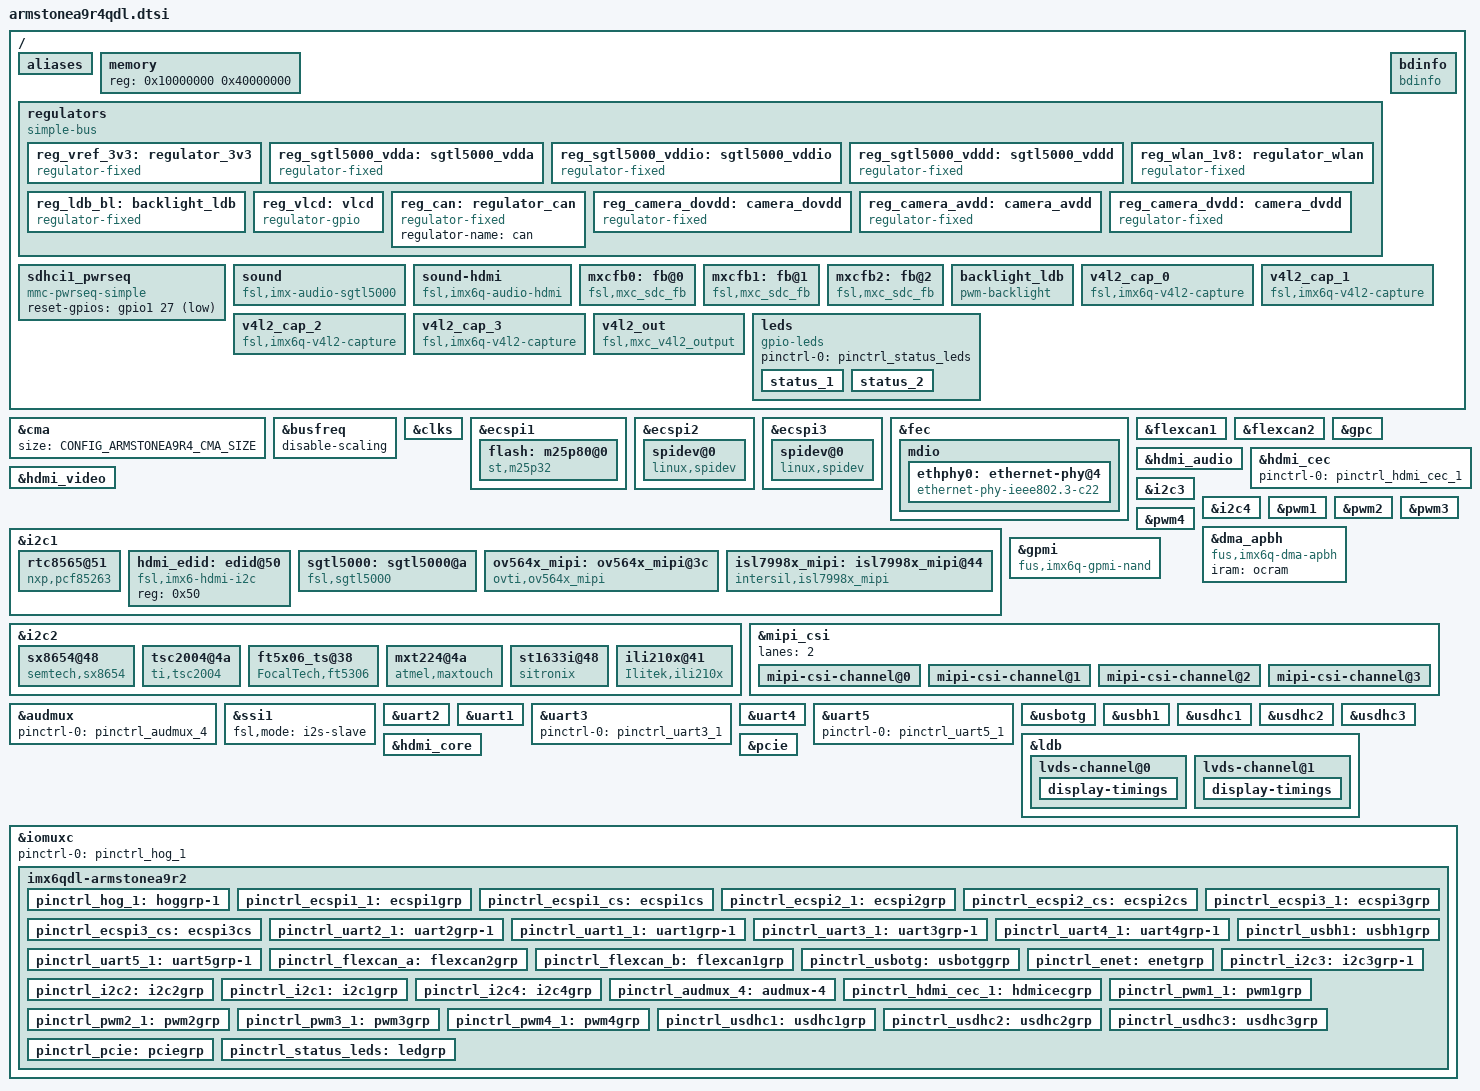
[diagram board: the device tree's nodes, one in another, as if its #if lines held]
/*
 * Copyright 2016-2017 F&S Elektronik Systeme GmbH
 *
 * This program is free software; you can redistribute it and/or modify
 * it under the terms of the GNU General Public License version 2 as
 * published by the Free Software Foundation.
 */

#include <dt-bindings/pwm/pwm.h>

/* Do we have HDMI? */
#if ((CONFIG_ARMSTONEA9R4_MXCFB0 == DISPLAY_HDMI) \
    || (CONFIG_ARMSTONEA9R4_MXCFB1 == DISPLAY_HDMI) \
    || (CONFIG_ARMSTONEA9R4_MXCFB2 == DISPLAY_HDMI))
#define CONFIG_ARMSTONEA9R4_HDMI
#define CONFIG_ARMSTONEA9R4_HDMI_AUDIO
#define CONFIG_ARMSTONEA9R4_HDMI_CEC
#if ((CONFIG_ARMSTONEA9R4_MXCFB0 == DISPLAY_HDMI) \
    || (CONFIG_ARMSTONEA9R4_MXCFB1 == DISPLAY_HDMI))
#define __HDMI_ON_0_OR_1__	1
#else
#define __HDMI_ON_0_OR_1__	0
#endif
#endif

/* Do we have LVDS0? */
#if ((CONFIG_ARMSTONEA9R4_MXCFB0 == DISPLAY_LVDS0) \
    || (CONFIG_ARMSTONEA9R4_MXCFB1 == DISPLAY_LVDS0) \
    || (CONFIG_ARMSTONEA9R4_MXCFB2 == DISPLAY_LVDS0))
#define CONFIG_ARMSTONEA9R4_LVDS0
#if ((CONFIG_ARMSTONEA9R4_MXCFB0 == DISPLAY_LVDS0) \
    || (CONFIG_ARMSTONEA9R4_MXCFB1 == DISPLAY_LVDS0))
#define __LVDS0_ON_0_OR_1__	1
#else
#define __LVDS0_ON_0_OR_1__	0
#endif
#endif

/* Do we have LVDS1? */
#if ((CONFIG_ARMSTONEA9R4_MXCFB0 == DISPLAY_LVDS1) \
    || (CONFIG_ARMSTONEA9R4_MXCFB1 == DISPLAY_LVDS1) \
    || (CONFIG_ARMSTONEA9R4_MXCFB2 == DISPLAY_LVDS1))
#define CONFIG_ARMSTONEA9R4_LVDS1
#if ((CONFIG_ARMSTONEA9R4_MXCFB0 == DISPLAY_LVDS1) \
    || (CONFIG_ARMSTONEA9R4_MXCFB1 == DISPLAY_LVDS1))
#define __LVDS1_ON_0_OR_1__	1
#else
#define __LVDS1_ON_0_OR_1__	0
#endif
#endif

/* Check which LVDS will be the primary display */
#if (CONFIG_ARMSTONEA9R4_MXCFB0 == DISPLAY_LVDS0)
#define __LVDS0_PRIMARY__
#elif (CONFIG_ARMSTONEA9R4_MXCFB0 == DISPLAY_LVDS1)
#define __LVDS1_PRIMARY__
#elif (CONFIG_ARMSTONEA9R4_MXCFB1 == DISPLAY_LVDS0)
#define __LVDS0_PRIMARY__
#elif (CONFIG_ARMSTONEA9R4_MXCFB1 == DISPLAY_LVDS1)
#define __LVDS1_PRIMARY__
#elif (CONFIG_ARMSTONEA9R4_MXCFB2 == DISPLAY_LVDS0)
#define __LVDS0_PRIMARY__
#elif (CONFIG_ARMSTONEA9R4_MXCFB2 == DISPLAY_LVDS1)
#define __LVDS1_PRIMARY__
#endif

/ {
	aliases {
		mxcfb0 = &mxcfb0;
		mxcfb1 = &mxcfb1;
		mxcfb2 = &mxcfb2;
		nand = &gpmi;
	};

	memory {
		reg = <0x10000000 0x40000000>;
	};

	regulators {
		compatible = "simple-bus";

		reg_vref_3v3: regulator_3v3 {
			compatible = "regulator-fixed";
			regulator-name = "vref-3V3";
			regulator-min-microvolt = <3300000>;
			regulator-max-microvolt = <3300000>;
			regulator-always-on;
		};

		/* USB_OTG_PWR handled by USB controller, no regulator needed */
#if 0 //###
		reg_usb_otg_vbus: usb_otg_vbus {
			compatible = "regulator-fixed";
			regulator-name = "usb_otg_vbus";
			regulator-min-microvolt = <5000000>;
			regulator-max-microvolt = <5000000>;
			gpio = <&gpio3 22 GPIO_ACTIVE_LOW>;
		};
#endif //###

		/* USB_H1_PWR is always on, no regulator needed */
#if 0 //###
		reg_usb_h1_vbus: usb_h1_vbus {
			compatible = "regulator-fixed";
			regulator-name = "usb_h1_vbus";
			regulator-min-microvolt = <5000000>;
			regulator-max-microvolt = <5000000>;
			/* No way to switch USB1_H1_VBUS power */
			regulator-always-on;
		};
#endif //###

#ifdef CONFIG_ARMSTONEA9R4_SGTL5000_AUDIO
		/* SGTL5000 analog voltage */
		reg_sgtl5000_vdda: sgtl5000_vdda {
			compatible = "regulator-fixed";
			regulator-name = "VDDA-supply";
			regulator-min-microvolt = <3000000>;
			regulator-max-microvolt = <3000000>;
			regulator-always-on;
		};

		/* SGTL5000 I/O voltage */
		reg_sgtl5000_vddio: sgtl5000_vddio {
			compatible = "regulator-fixed";
			regulator-name = "VDDIO-supply";
			regulator-min-microvolt = <3300000>;
			regulator-max-microvolt = <3300000>;
			regulator-always-on;
		};

		/* SGTL5000 internal digital voltage */
		reg_sgtl5000_vddd: sgtl5000_vddd {
			compatible = "regulator-fixed";
			regulator-name = "VDDD-supply";
			regulator-min-microvolt = <1500000>;
			regulator-max-microvolt = <1500000>;
			regulator-always-on;
		};
#endif /* CONFIG_ARMSTONEA9R4_SGTL5000_AUDIO */

#ifdef CONFIG_ARMSTONEA9R4_WLAN
		reg_wlan_1v8: regulator_wlan {
			compatible = "regulator-fixed";
			regulator-name = "vqmmc-wlan-1v8";
			regulator-min-microvolt = <1800000>;
			regulator-max-microvolt = <1800000>;
			regulator-always-on;
		};
#endif

		/* backlight ldb */
		reg_ldb_bl: backlight_ldb {
			compatible = "regulator-fixed";
			regulator-name = "ldb-bl";
			gpio = <&gpio2 8 GPIO_ACTIVE_HIGH>;
			regulator-min-microvolt = <3300000>;
			regulator-max-microvolt = <3300000>;
			enable-active-high;
		};

		/* LCD power on voltage */
		reg_vlcd: vlcd {
			compatible = "regulator-gpio";
			regulator-name = "VLCD";
			regulator-min-microvolt = <3300000>;
			regulator-max-microvolt = <5000000>;

			enable-gpio = <&gpio2 11 GPIO_ACTIVE_HIGH>;
			gpios = <&gpio3 30 GPIO_ACTIVE_HIGH>;
#ifdef CONFIG_ARMSTONEA9R4_LVDS_3_3_V
			gpios-states = <0>;
#elif defined(CONFIG_ARMSTONEA9R4_LVDS_5_0_V)
			gpios-states = <1>;
#endif
			states = <5000000 0x1
				3300000 0x0>;
			enable-active-high;
		};

		/* CAN */
		reg_can: regulator_can {
			compatible = "regulator-fixed";
			regulator-name = "can";
		};

#ifdef CONFIG_ARMSTONEA9R4_SERIAL_CAMERA
		reg_camera_dovdd: camera_dovdd {
			compatible = "regulator-fixed";
			regulator-name = "DOVDD-supply";
			regulator-min-microvolt = <1800000>;
			regulator-max-microvolt = <1800000>;
		};

		reg_camera_avdd: camera_avdd {
			compatible = "regulator-fixed";
			regulator-name = "VAVDD-supply";
			regulator-min-microvolt = <2800000>;
			regulator-max-microvolt = <2800000>;
		};

		reg_camera_dvdd: camera_dvdd {
			compatible = "regulator-fixed";
			regulator-name = "DVDD-supply";
			regulator-min-microvolt = <1500000>;
			regulator-max-microvolt = <1500000>;
		};
#endif /* CONFIG_ARMSTONEA9R4_SERIAL_CAMERA */
	};

	/* F&S board information */
	bdinfo: bdinfo {
		compatible = "bdinfo";
		board_name = "armstonea9r2";
		ecc_strength = "8";
	};

	sdhci1_pwrseq: sdhci1_pwrseq {
		compatible = "mmc-pwrseq-simple";
		reset-gpios = <&gpio1 27 GPIO_ACTIVE_LOW>;
	};

#ifdef CONFIG_ARMSTONEA9R4_SGTL5000_AUDIO
	sound {
		compatible = "fsl,imx-audio-sgtl5000";
		cpu-dai = <&ssi1>;
		audio-codec = <&sgtl5000>;
		model = "imx-sgtl5000";
		mux-int-port = <1>;  /* SSI1=1, SSI2=2, SSI3=7 */
		mux-ext-port = <4>;
		audio-routing =
//			"MIC_IN", "Mic Jack",
			"Mic Jack", "Mic Bias",
			"LINE_IN", "Line In Jack";
//			"Line Out Jack", "LINE_OUT";
	};
#endif

#ifdef CONFIG_ARMSTONEA9R4_HDMI_AUDIO
	sound-hdmi {
		compatible = "fsl,imx6q-audio-hdmi", "fsl,imx-audio-hdmi";
		model = "imx-audio-hdmi";
		hdmi-controller = <&hdmi_audio>;
	};
#endif

	mxcfb0: fb@0 {
		compatible = "fsl,mxc_sdc_fb";
		late_init = <0>;
#if (CONFIG_ARMSTONEA9R4_MXCFB0 == DISPLAY_HDMI)
		disp_dev = "hdmi";
		default_bpp = <CONFIG_ARMSTONEA9R4_HDMI_BPP>;
		interface_pix_fmt = CONFIG_ARMSTONEA9R4_HDMI_PIX_FMT;
		int_clk = <0>;
		mode_str = CONFIG_ARMSTONEA9R4_HDMI_MODE_STR;
#elif (CONFIG_ARMSTONEA9R4_MXCFB0 == DISPLAY_LVDS0)
		disp_dev = "ldb";
		default_bpp = <CONFIG_ARMSTONEA9R4_LVDS0_BPP>;
		interface_pix_fmt = CONFIG_ARMSTONEA9R4_LVDS0_PIX_FMT;
		int_clk = <1>;
#elif (CONFIG_ARMSTONEA9R4_MXCFB0 == DISPLAY_LVDS1)
		disp_dev = "ldb";
		default_bpp = <CONFIG_ARMSTONEA9R4_LVDS1_BPP>;
		interface_pix_fmt = CONFIG_ARMSTONEA9R4_LVDS1_PIX_FMT;
		int_clk = <1>;
#else
		status = "disabled";
#endif
	};

	mxcfb1: fb@1 {
		compatible = "fsl,mxc_sdc_fb";
		late_init = <0>;
#if (CONFIG_ARMSTONEA9R4_MXCFB1 == DISPLAY_HDMI)
		disp_dev = "hdmi";
		default_bpp = <CONFIG_ARMSTONEA9R4_HDMI_BPP>;
		interface_pix_fmt = CONFIG_ARMSTONEA9R4_HDMI_PIX_FMT;
		int_clk = <0>;
		mode_str = CONFIG_ARMSTONEA9R4_HDMI_MODE_STR;
#elif (CONFIG_ARMSTONEA9R4_MXCFB1 == DISPLAY_LVDS0)
		disp_dev = "ldb";
		default_bpp = <CONFIG_ARMSTONEA9R4_LVDS0_BPP>;
		interface_pix_fmt = CONFIG_ARMSTONEA9R4_LVDS0_PIX_FMT;
		int_clk = <1>;
#elif (CONFIG_ARMSTONEA9R4_MXCFB1 == DISPLAY_LVDS1)
		disp_dev = "ldb";
		default_bpp = <CONFIG_ARMSTONEA9R4_LVDS1_BPP>;
		interface_pix_fmt = CONFIG_ARMSTONEA9R4_LVDS1_PIX_FMT;
		int_clk = <1>;
#else
		status = "disabled";
#endif
	};

	mxcfb2: fb@2 {
		compatible = "fsl,mxc_sdc_fb";
		late_init = <0>;
#if (CONFIG_ARMSTONEA9R4_MXCFB2 == DISPLAY_HDMI)
		disp_dev = "hdmi";
		default_bpp = <CONFIG_ARMSTONEA9R4_HDMI_BPP>;
		interface_pix_fmt = CONFIG_ARMSTONEA9R4_HDMI_PIX_FMT;
		int_clk = <0>;
		mode_str = CONFIG_ARMSTONEA9R4_HDMI_MODE_STR;
#elif (CONFIG_ARMSTONEA9R4_MXCFB2 == DISPLAY_LVDS0)
		disp_dev = "ldb";
		default_bpp = <CONFIG_ARMSTONEA9R4_LVDS0_BPP>;
		interface_pix_fmt = CONFIG_ARMSTONEA9R4_LVDS0_PIX_FMT;
		int_clk = <1>;
#elif (CONFIG_ARMSTONEA9R4_MXCFB2 == DISPLAY_LVDS1)
		disp_dev = "ldb";
		default_bpp = <CONFIG_ARMSTONEA9R4_LVDS1_BPP>;
		interface_pix_fmt = CONFIG_ARMSTONEA9R4_LVDS1_PIX_FMT;
		int_clk = <1>;
#else
		status = "disabled";
#endif
	};

	/* LVDS backlight PWM (PWM3) */
	backlight_ldb {
		compatible = "pwm-backlight";
		power-supply = <&reg_ldb_bl>;
#ifndef DISPLAY_LVDS_CHIMEI
		pwms = <&pwm3 0 250000 PWM_POLARITY_INVERTED>;
		brightness-levels = <135 143 151 159 167 175 183 191
				     199 207 215 223 231 239 247 255>;
#else
		pwms = <&pwm3 0 5000000 0>;
		brightness-levels = <0 1 5 10 18 28 41 56
				     73 92 113 137 163 192 222 255>;
#endif
		default-brightness-level = <14>;
		fb-names = "ldb0", "ldb1";
	};

/* mipi camera interface */
#ifdef CONFIG_ARMSTONEA9R4_SERIAL_CAMERA
	v4l2_cap_0 {
		compatible = "fsl,imx6q-v4l2-capture";
		ipu_id = <0>;
		csi_id = <0>;
		mclk_source = <0>;
		status = "okay";
	};

	/* Second capture device, for second MIPI channel */
	v4l2_cap_1 {
		compatible = "fsl,imx6q-v4l2-capture";
		ipu_id = <0>;
		csi_id = <1>;
		mclk_source = <0>;
		status = "okay";
	};

#ifndef CONFIG_ARMSTONEA9R4_USE_ONE_IPU
	/* Third capture device, for third MIPI channel */
	v4l2_cap_2 {
		compatible = "fsl,imx6q-v4l2-capture";
		ipu_id = <1>;
		csi_id = <0>;
		mclk_source = <0>;
		status = "okay";
	};

	/* Fourth capture device, for fourth MIPI channel */
	v4l2_cap_3 {
		compatible = "fsl,imx6q-v4l2-capture";
		ipu_id = <1>;
		csi_id = <1>;
		mclk_source = <0>;
		status = "okay";
	};
#endif
#endif

	v4l2_out {
		compatible = "fsl,mxc_v4l2_output";
		status = "okay";
	};

	leds {
		compatible = "gpio-leds";
		pinctrl-names = "default";
		pinctrl-0 = <&pinctrl_status_leds>;

		status_1 {
			label = "Status1";
			gpios = <&gpio7 13 GPIO_ACTIVE_HIGH>;
			default-state = "keep";
		};

		status_2 {
			label = "Status2";
			gpios = <&gpio7 12 GPIO_ACTIVE_HIGH>;
			default-state = "keep";
		};
	};

/* Matrix Keypad not configurated yet, some pins can be multiple declared*/
#if 0
		matrix-keypad {
		compatible = "gpio-matrix-keypad";
		pinctrl-names = "default";
		pinctrl-0 = <&pinctrl_gpio_matrix_keypad>;
		debounce-delay-ms = <10>;
		col-scan-delay-us = <2>;
		linux,no-autorepeat;

		row-gpios = <&gpio5 28 0
			     &gpio3 28 0
			     &gpio5 29 0
			     &gpio3 29 0
			     &gpio3 19 0
			     &gpio3 24 0
			     &gpio3 20 0
			     &gpio3 25 0
			     >;

		col-gpios = <&gpio4 21 0
			     &gpio3 0 0
			     &gpio4 24 0
			     &gpio3 1 0
			     &gpio4 22 0
			     &gpio3 2 0
			     &gpio4 23 0
			     &gpio3 3 0>;
		/* needs to be configurated, Vybrid Kernel has so config file
		 * "fs-matrix-keypad.h" */
		linux,keymap = <>;
	};
#endif

};

/* RAM size for Continuous Memory Allocator; if not defined, use 320 MB */
#ifndef CONFIG_ARMSTONEA9R4_CMA_SIZE
#define CONFIG_ARMSTONEA9R4_CMA_SIZE 0x14000000
#endif
&cma {
	size = <CONFIG_ARMSTONEA9R4_CMA_SIZE>;
};

&busfreq {
	/* Disable bus frequency scaling, because reducing bus frequency to
	   24 MHz does not work with all types of DDR3 RAM */
	disable-scaling;
};

/* CKO (via CKO1): 24.576 MHz for Audio Codec, CKO2: 24 MHz for Camera. */
&clks {
	assigned-clocks =
#ifdef CONFIG_ARMSTONEA9R4_LVDS0_CLK
			  <&clks IMX6QDL_CLK_LDB_DI0_SEL>,
#endif
#ifdef CONFIG_ARMSTONEA9R4_LVDS1_CLK
			  <&clks IMX6QDL_CLK_LDB_DI1_SEL>,
#endif
			  <&clks IMX6QDL_CLK_PLL4_AUDIO_DIV>,
			  <&clks IMX6QDL_CLK_CKO1_SEL>,
			  <&clks IMX6QDL_CLK_CKO1_PODF>,
			  <&clks IMX6QDL_CLK_CKO>,
			  <&clks IMX6QDL_CLK_CKO2_SEL>;

	assigned-clock-parents =
#ifdef CONFIG_ARMSTONEA9R4_LVDS0_CLK
				 <&clks CONFIG_ARMSTONEA9R4_LVDS0_CLK>,
#endif
#ifdef CONFIG_ARMSTONEA9R4_LVDS1_CLK
				 <&clks CONFIG_ARMSTONEA9R4_LVDS1_CLK>,
#endif
				 <0>,
				 <&clks IMX6QDL_CLK_PLL4_AUDIO_DIV>,
				 <0>,
				 <&clks IMX6QDL_CLK_CKO1>,
 				 <&clks IMX6QDL_CLK_OSC>;

	/*
	 * The Audio-PLL (PLL4) must have at least 650MHz. The PLL post divider
	 * can divide by 1, 2 and 4, which means the lowest possible frequency
	 * is 162.5 MHz. The largest PODF divider for CKO1 is 8, so we do not
	 * get below 20 MHz. Use 24.576 MHz as this is a multiple of the most
	 * commonly used bit rates.
	 *
	 * Remark: Solo and DualLite have an additional divider that also can
	 * divide by 1, 2 and 4. So here we can go down to 12.288 MHz.
	 */
	assigned-clock-rates =
#ifdef CONFIG_ARMSTONEA9R4_LVDS0_CLK
			      <0>,
#endif
#ifdef CONFIG_ARMSTONEA9R4_LVDS1_CLK
			      <0>,
#endif
#ifdef CONFIG_ARMSTONEA9R4_AUDIO_12M288
			      <98304000>,	/* Audio with 12.288 MHz */
			      <98304000>,
			      <12288000>,
#else
			      <196608000>,	/* Audio with 24.576 MHz */
			      <196608000>,
			      <24576000>,
#endif
			      <24000000>;
};

#ifdef CONFIG_ARMSTONEA9R4_SPI_FLASH
/* Optional on-board SPI flash (1x CS) */
&ecspi1 {
	fsl,spi-num-chipselects = <2>;
	cs-gpios = <&gpio2 30 GPIO_ACTIVE_HIGH>;
	pinctrl-names = "default";
	pinctrl-0 = <&pinctrl_ecspi1_1 &pinctrl_ecspi1_cs>;
	status = "okay";

	flash: m25p80@0 {
		#address-cells = <1>;
		#size-cells = <1>;
		compatible = "st,m25p32";
		spi-max-frequency = <20000000>;
		reg = <0>;
	};
};
#endif /* CONFIG_ARMSTONEA9R4_SPI_FLASH */

#ifdef CONFIG_ARMSTONEA9R4_SPI_A
/* SPI_A (1x CS) */
&ecspi2 {
	fsl,spi-num-chipselects = <2>;
	cs-gpios = <&gpio2 26 GPIO_ACTIVE_HIGH>;
	pinctrl-names = "default";
	pinctrl-0 = <&pinctrl_ecspi2_1 &pinctrl_ecspi2_cs>;
	status = "okay";

	spidev@0 {
		#address-cells = <1>;
		#size-cells = <1>;
		compatible = "linux,spidev";
		spi-max-frequency = <20000000>;
		reg = <0>;
	};
};
#endif /* CONFIG_ARMSTONEA9R4_SPI_A */

#ifdef CONFIG_ARMSTONEA9R4_SPI_B
/* SPI_B (1x CS) */
&ecspi3 {
	fsl,spi-num-chipselects = <2>;
	cs-gpios = <&gpio4 24 GPIO_ACTIVE_HIGH>;
	pinctrl-names = "default";
	pinctrl-0 = <&pinctrl_ecspi3_1 &pinctrl_ecspi3_cs>;
	status = "okay";

	spidev@0 {
		#address-cells = <1>;
		#size-cells = <1>;
		compatible = "linux,spidev";
		spi-max-frequency = <20000000>;
		reg = <0>;
	};
};
#endif /* CONFIG_ARMSTONEA9R4_SPI_B */

&fec {
	pinctrl-names = "default";
	pinctrl-0 = <&pinctrl_enet>;
	phy-mode = "rgmii-id";
	phy-handle = <&ethphy0>;
	phy-supply = <&reg_vref_3v3>;
	status = "okay";

	mdio {
		#address-cells = <1>;
		#size-cells = <0>;

		ethphy0: ethernet-phy@4 {
			compatible = "ethernet-phy-ieee802.3-c22";
			reg = <4>;
			/* Set the maximum link speed if required */
			//max-speed = <100>;
			rtl821x,aldps-enable;
			rtl821x,ssc-rxc-enable;
			rtl821x,ssc-sysclk-enable;
			rtl821x,ssc-clkout-enable;
			rtl821x,led-link = <2>;
			rtl821x,led-act = <1>;
		};
	};
};

/* CANRX2 J13 Pin 3 & CANTX2 Pin 4 */
&flexcan1 {
	pinctrl-names = "default";
	pinctrl-0 = <&pinctrl_flexcan_b>;
	xceiver-supply = <&reg_can>;
	status = "okay";
};

/* CANRX1 Pin 63 & CANTX1 Pin 64 */
&flexcan2 {
	pinctrl-names = "default";
	pinctrl-0 = <&pinctrl_flexcan_a>;
	xceiver-supply = <&reg_can>;
	status = "okay";
};

&gpc {
	fsl,cpu_pupscr_sw2iso = <0xf>;
	fsl,cpu_pupscr_sw = <0xf>;
	fsl,cpu_pdnscr_iso2sw = <0x1>;
	fsl,cpu_pdnscr_iso = <0x1>;
	fsl,ldo-bypass = <1>; /* use ldo-bypass, u-boot will check it and configure */
	fsl,wdog-reset = <1>; /* watchdog select of reset source */
};

#ifdef CONFIG_ARMSTONEA9R4_HDMI_AUDIO
&hdmi_audio {
	status = "okay";
};
#endif

#ifdef CONFIG_ARMSTONEA9R4_HDMI_CEC
&hdmi_cec {
	pinctrl-names = "default";
	pinctrl-0 = <&pinctrl_hdmi_cec_1>;
	status = "okay";
};
#endif

#ifdef CONFIG_ARMSTONEA9R4_HDMI
&hdmi_video {
	fsl,phy_reg_vlev = <0x0294>;
	fsl,phy_reg_cksymtx = <0x800d>;
	force-dvi-mode;
	status = "okay";
};
#endif

#ifdef CONFIG_ARMSTONEA9R4_I2C_C
/* additional bus on pins 18, 26 */
&i2c1 {
	clock-frequency = <100000>;
	pinctrl-names = "default";
	pinctrl-0 = <&pinctrl_i2c1>;
	status = "okay";

	rtc8565@51 {
		compatible = "nxp,pcf85263";
		reg = <0x51>;
		interrupt-parent = <&gpio1>;
		interrupts = <28 IRQ_TYPE_EDGE_FALLING>;
	};

#ifdef CONFIG_ARMSTONEA9R4_HDMI
	hdmi_edid: edid@50 {
		compatible = "fsl,imx6-hdmi-i2c";
		reg = <0x50>;
	};
#endif

#ifdef CONFIG_ARMSTONEA9R4_SGTL5000_AUDIO
	sgtl5000: sgtl5000@a {
		compatible = "fsl,sgtl5000";
		reg = <0x0a>;
		mono2both;
		lrclk-strength = <3>;
		clocks = <&clks IMX6QDL_CLK_CKO>;
		VDDA-supply = <&reg_sgtl5000_vdda>;
		VDDIO-supply = <&reg_sgtl5000_vddio>;
		VDDD-supply = <&reg_sgtl5000_vddd>;
	};
#endif


/* If you want to use mipi camera you have to check the clock because cko2
 * is used by sgtl5000 audio driver so you have to change the &clk node to
 * ck01. Therefore you have to set PLL_AUDIO, CCM_ANALOG_MISC2n[MSB:LSB] */
#ifdef CONFIG_ARMSTONEA9R4_SERIAL_CAMERA
	ov564x_mipi: ov564x_mipi@3c {
		compatible = "ovti,ov564x_mipi";
		reg = <0x3c>;
		/* derived from IMX6QDL_CLK_CKO2 */
		clocks = <&clks IMX6QDL_CLK_CKO2>;
		clock-names = "csi_mclk";
		DOVDD-supply = <&reg_camera_dovdd>; /* 1.8v */
		AVDD-supply = <&reg_camera_avdd>;  /* 2.8v, rev C board is VGEN3
						rev B board is VGEN5 */
		DVDD-supply = <&reg_camera_dvdd>;  /* 1.5v*/
		pwn-gpios = <&gpio5 24 GPIO_ACTIVE_HIGH>;
		/* With our camera adapter we dont need a reset pin because the
		 * reset will be automatically generated on our adapter. Other
		 * cameras maybe need a gpio to perform a reset. */
		/* rst-gpios = <dummy>; */
		csi_id = <0>;
		v_channel_id = <0>;
		mclk = <24000000>;		/* OSC out */
		mclk_source = <0>;
	};
#ifdef CONFIG_ARMSTONEA9R4_MIPI_CAMERA_ISL7998X
	isl7998x_mipi: isl7998x_mipi@44 {
		compatible = "intersil,isl7998x_mipi";
		reg = <0x44>;
		clocks = <&clks IMX6QDL_CLK_CKO2>;	/* Dummy */
		clock-names = "csi_mclk";
		mclk = <27000000>;		/* Has own oscillator */
	};
#endif
#endif /* CONFIG_ARMSTONEA9R4_SERIAL_CAMERA */
};
#endif /* CONFIG_ARMSTONEA9R4_I2C_C */

#ifdef CONFIG_ARMSTONEA9R4_I2C_B
&i2c2 {
	clock-frequency = <100000>;
	pinctrl-names = "default";
	pinctrl-0 = <&pinctrl_i2c2>;
	status = "okay";

#ifdef CONFIG_ARMSTONEA9R4_4WTOUCH_SX8655
	/* 4/5 wire analog resistive touch on Touch Connector (I2C) */
	sx8654@48 {
		compatible = "semtech,sx8654";
		reg = <0x48>;
		touchrate = <0x30>;
		powdly = <0x06>;
		filt = <0x02>;
		setdly = <0x08>;
		pinctrl-names = "default";
		/* There are 2 irq pins for I2C2. You can either chose the irq from the
		 * lvds connector or from the hirose connector. below is the
		 * interrupt from lvds connector defined. Only one interrupt can
		 * be used for one touch. It is only possible if revision >= 1.20 and
		 * R223 is not mounted. If R223 is mounted we have the VLCD signal
		 * on the IRQ pin on LVDS connector (J11/26).
		 */
//#if (CONFIG_ARMSTONEA9R4_BOARD_REVISION >= 120)
		//interrupt-parent = <&gpio2>;
		//interrupts = <13 IRQ_TYPE_EDGE_FALLING>;
//#else
		interrupt-parent = <&gpio1>;
		interrupts = <30 IRQ_TYPE_EDGE_FALLING>;
		reset-gpio = <&gpio1 29 GPIO_ACTIVE_LOW>;
//#endif
	};
#endif

#ifdef CONFIG_ARMSTONEA9R4_4WTOUCH_TSC2004
	/* 4/5 wire analog resistive touch on Touch Connector (I2C) */
	tsc2004@4a {
		compatible = "ti,tsc2004";
		reg = <0x4a>;
		vio-supply = <&reg_vref_3v3>;
		interrupts-extended = <&gpio1 30 IRQ_TYPE_EDGE_FALLING>;
		reset-gpio = <&gpio1 29 GPIO_ACTIVE_LOW>;
		touchscreen-fuzz-x = <4>;
		touchscreen-fuzz-y = <7>;
		touchscreen-fuzz-pressure = <20>;
		touchscreen-size-x = <4096>;
		touchscreen-size-y = <4096>;
		touchscreen-max-pressure = <2048>;
		touchscreen-inverted-y;
		ti,x-plate-ohms = <280>;
		ti,pre-charge-time = <4>;
		ti,sense-time-sel = <3>;
	};
#endif

#ifdef CONFIG_ARMSTONEA9R4_CAPTOUCH_FT5x06
	/* F&S driver V3.0 on Touch Connector (I2C) */
	ft5x06_ts@38 {
		compatible = "FocalTech,ft5306";
		reg = <0x38>;
		fingers = <2>;
		touchscreen-size-x = <800>;
		touchscreen-size-y = <480>;
		threshold = <25>;
		/* There are 2 irq pins for I2C2. You can either chose the irq from the
		 * lvds connector or from the hirose connector. below is the
		 * interrupt from lvds connector defined. Only one interrupt can
		 * be used for one touch. It is only possible if revision >= 1.20 and
		 * R223 is not mounted. If R223 is mounted we have the VLCD signal
		 * on the IRQ pin on LVDS connector (J11/26).
		 */
//#if (CONFIG_ARMSTONEA9R4_BOARD_REVISION >= 120)
		//interrupt-parent = <&gpio2>;
		//interrupts = <13 IRQ_TYPE_EDGE_FALLING>;
//#else
		interrupt-parent = <&gpio1>;
		interrupts = <30 IRQ_TYPE_EDGE_FALLING>;
//#endif
		reset-gpios = <&gpio1 29 GPIO_ACTIVE_LOW>;
		x-rev;
		y-rev;
		linux,wakeup;
	};
#endif

#ifdef CONFIG_ARMSTONEA9R4_CAPTOUCH_MXT224
	/* Atmel PCAP touch on Touch Connector (I2C) */
	mxt224@4a {
		compatible = "atmel,maxtouch";
		reg = <0x4a>;
		/* There are 2 irq pins for I2C2. You can either chose the irq from the
		 * lvds connector or from the hirose connector. below is the
		 * interrupt from lvds connector defined. Only one interrupt can
		 * be used for one touch. It is only possible if revision >= 1.20 and
		 * R223 is not mounted. If R223 is mounted we have the VLCD signal
		 * on the IRQ pin on LVDS connector (J11/26).
		 */
//#if (CONFIG_ARMSTONEA9R4_BOARD_REVISION >= 120)
		//interrupt-parent = <&gpio2>;
		//interrupts = <13 IRQ_TYPE_EDGE_FALLING>;
//#else
		interrupt-parent = <&gpio1>;
		interrupts = <30 IRQ_TYPE_EDGE_FALLING>;
//#endif
		atmel,cfg_name = "atmel/mxt224.cfg";
		atmel,reset-gpio = <&gpio1 29 GPIO_ACTIVE_LOW>;
	};
#endif

#ifdef CONFIG_ARMSTONEA9_CAPTOUCH_SITRONIX
	/* Sitronix PCAP touch on Touch-Connector (I2C) */
	st1633i@48 {
		compatible = "sitronix";
		reg = <0x48>;
		swap-xy;
		/* There are 2 irq pins for I2C2. You can either chose the irq from the
		 * lvds connector or from the hirose connector. below is the
		 * interrupt from lvds connector defined. Only one interrupt can
		 * be used for one touch. It is only possible if revision >= 1.20 and
		 * R223 is not mounted. If R223 is mounted we have the VLCD signal
		 * on the IRQ pin on LVDS connector (J11/26).
		 */
//#if (CONFIG_ARMSTONEA9R4_BOARD_REVISION >= 120)
		//interrupt-parent = <&gpio2>;
		//interrupts = <13 IRQ_TYPE_EDGE_FALLING>;
//#else
		interrupt-parent = <&gpio1>;
		interrupts = <30 IRQ_TYPE_EDGE_FALLING>;
//#endif
		reset-gpio = <&gpio1 29 GPIO_ACTIVE_LOW>;
	};
#endif

#ifdef CONFIG_ARMSTONEA9_CAPTOUCH_ILITEK
	/* Ilitek PCAP touch on Touch-Connector (I2C) */
	ili210x@41 {
		compatible = "Ilitek,ili210x";
		reg = <0x41>;
		/* There are 2 irq pins for I2C2. You can either chose the irq from the
		 * lvds connector or from the hirose connector. below is the
		 * interrupt from lvds connector defined. Only one interrupt can
		 * be used for one touch. It is only possible if revision >= 1.20 and
		 * R223 is not mounted. If R223 is mounted we have the VLCD signal
		 * on the IRQ pin on LVDS connector (J11/26).
		 */
//#if (CONFIG_ARMSTONEA9R4_BOARD_REVISION >= 120)
		//interrupt-parent = <&gpio2>;
		//interrupts = <13 IRQ_TYPE_EDGE_FALLING>;
//#else
		interrupt-parent = <&gpio1>;
		interrupts = <30 IRQ_TYPE_EDGE_FALLING>;
//#endif
		reset-gpio = <&gpio1 29 GPIO_ACTIVE_LOW>;
	};
#endif
};
#endif /* CONFIG_ARMSTONEA9R4_I2C_B */

#ifdef CONFIG_ARMSTONEA9R4_I2C_A
&i2c3 {
	clock-frequency = <100000>;
	pinctrl-names = "default";
	pinctrl-0 = <&pinctrl_i2c3>;
	status = "okay";
	/* define ADC here */
};
#endif /* CONFIG_ARMSTONEA9R4_I2C_A */

#ifdef CONFIG_ARMSTONEA9R4_I2C_D
&i2c4 {
	clock-frequency = <100000>;
	pinctrl-names = "default";
	pinctrl-0 = <&pinctrl_i2c4>;
	status = "okay";
};
#endif /* CONFIG_ARMSTONEA9R4_I2C_D */

/* PWM_B (Pin 30) */
&pwm1 {
	pinctrl-names = "default";
	pinctrl-0 = <&pinctrl_pwm1_1>;
	keep-power;		/* Necessary if PWM is inverted */
	status = "okay";
};
/* PWM_C (Pin 32) */
&pwm2 {
	pinctrl-names = "default";
	pinctrl-0 = <&pinctrl_pwm2_1>;
	keep-power;		/* Necessary if PWM is inverted */
	status = "okay";
};

/* Backlight PWM (J12 Pin 3) */
&pwm3 {
	pinctrl-names = "default";
	pinctrl-0 = <&pinctrl_pwm3_1>;
	#pwm-cells = <3>;
	keep-power;		/* Necessary if PWM is inverted */
	status = "okay";
};

/* PWM_A (Pin 28) */
&pwm4 {
	pinctrl-names = "default";
	pinctrl-0 = <&pinctrl_pwm4_1>;
	keep-power;		/* Necessary if PWM is inverted */
	status = "okay";
};

&dma_apbh {
	/* Switch to F&S implementation of APBH DMA driver for GPMI (NAND) */
	compatible = "fus,imx6q-dma-apbh", "fus,imx28-dma-apbh";
	iram = <&ocram>;
};

#ifdef CONFIG_ARMSTONEA9R4_NAND
&gpmi {
	/* Switch to F&S implementation of GPMI NAND driver */
	compatible = "fus,imx6q-gpmi-nand";
	pinctrl-names = "default";
//###	pinctrl-0 = <&pinctrl_gpmi_nand_1>;
	fus,skipblocks = <2>;
	fus,chunk1k;
	fus,ecc_strength = <8>; 	/* Spare area 64 bytes */
	//fus,ecc_strength = <40>;	/* Spare area 224 bytes */
	status = "okay";
};
#endif

#ifdef CONFIG_ARMSTONEA9R4_SERIAL_CAMERA
&mipi_csi {
	status = "okay";
	lanes = <2>;

	mipi-csi-channel@0 {
		ipu_id = <0>;
		csi_id = <0>;
		v_channel = <0>;
		status = "okay";
	};

	mipi-csi-channel@1 {
		ipu_id = <0>;
		csi_id = <1>;
		v_channel = <1>;
		status = "okay";
	};

#ifndef CONFIG_ARMSTONEA9R4_USE_ONE_IPU
	mipi-csi-channel@2 {
		ipu_id = <1>;
		csi_id = <0>;
		v_channel = <2>;
		status = "okay";
	};

	mipi-csi-channel@3 {
		ipu_id = <1>;
		csi_id = <1>;
		v_channel = <3>;
		status = "okay";
	};
#endif
};
#endif

#ifdef CONFIG_ARMSTONEA9R4_SGTL5000_AUDIO
&audmux {
	pinctrl-names = "default";
	pinctrl-0 = <&pinctrl_audmux_4>;
	status = "okay";
};

&ssi1 {
	fsl,mode = "i2s-slave";
	status = "okay";
};
#endif /* CONFIG_ARMSTONEA9R4_SGTL5000_AUDIO */

#ifdef CONFIG_ARMSTONEA9R4_UART_A
/* UART2 TX/RX on pins 13,15 RTS/CTS on 19,21 */
&uart2 {
	pinctrl-names = "default";
	pinctrl-0 = <&pinctrl_uart2_1>;
#ifdef CONFIG_ARMSTONEA9R4_UART_A_RTSCTS
	uart-has-rtscts;
#endif
	status = "okay";
};
#endif /* CONFIG_ARMSTONEA9R4_UART_A */

#ifdef CONFIG_ARMSTONEA9R4_UART_B
/* UART1 TX/RX on pins 18,20 RTS/CTS on 22,24 */
&uart1 {
	pinctrl-names = "default";
	pinctrl-0 = <&pinctrl_uart1_1>;
#ifdef CONFIG_ARMSTONEA9R4_UART_B_RTSCTS
	uart-has-rtscts;
#endif
	status = "okay";
};
#endif /* CONFIG_ARMSTONEA9R4_UART_B */

#ifdef CONFIG_ARMSTONEA9R4_UART_C
/* UART3 TX/RX on pins 23, 25 (port C) */
&uart3 {
	pinctrl-names = "default";
	pinctrl-0 = <&pinctrl_uart3_1>;
	status = "okay";
};
#endif /* CONFIG_ARMSTONEA9R4_UART_C */

#ifdef CONFIG_ARMSTONEA9R4_UART_D
/* UART4 on pins 55-58 (debug port D)*/
&uart4 {
	pinctrl-names = "default";
	pinctrl-0 = <&pinctrl_uart4_1>;
#ifdef CONFIG_ARMSTONEA9R4_UART_D_RTSCTS
	uart-has-rtscts;
#endif
	status = "okay";
};
#endif /* CONFIG_ARMSTONEA9R4_UART_D */

#ifdef CONFIG_ARMSTONEA9R4_UART_E
/* UART5 RX/TX on pins 36, 38 (port E) */
&uart5 {
	pinctrl-names = "default";
	pinctrl-0 = <&pinctrl_uart5_1>;
	status = "okay";
};
#endif /* CONFIG_ARMSTONEA9R4_UART_E */

&usbotg {
	pinctrl-names = "default";
	pinctrl-0 = <&pinctrl_usbotg>;
//###	vbus-supply = <&reg_usb_otg_vbus>;
	disable-over-current;
	status = "okay";
};

&usbh1 {
	pinctrl-names = "default";
	pinctrl-0 = <&pinctrl_usbh1>;
//###	vbus-supply = <&reg_usb_h1_vbus>;
	disable-over-current;
	status = "okay";
};

#ifdef CONFIG_ARMSTONEA9R4_WLAN
&usdhc1 {
	/* on-board WLAN/BT */
	pinctrl-names = "default";
	pinctrl-0 = <&pinctrl_usdhc1>;
	/* WLAN is non-removable, but CD tells us if it is equipped or not */
	cd-gpios = <&gpio1 1 GPIO_ACTIVE_LOW>;
	//non-removable;
	bus-width = <4>;
	vmmc-supply = <&reg_vref_3v3>;	/* VDD */
	vqmmc-supply = <&reg_wlan_1v8>;	/* VDD_IO */
	voltage-ranges = <1800 1800>;
	keep-power-in-suspend;
	enable-sdio-wakeup;
	mmc-pwrseq = <&sdhci1_pwrseq>;
	status = "okay";
};
#endif

#ifdef CONFIG_ARMSTONEA9R4_SD_A
&usdhc2 {
	/* Micro-SD-Card-Slot, CD is active low */
	pinctrl-names = "default";
	pinctrl-0 = <&pinctrl_usdhc2>;
	cd-gpios = <&gpio1 4 GPIO_ACTIVE_LOW>;
	bus-width = <4>;
	vmmc-supply = <&reg_vref_3v3>;	/* VDD */
	vqmmc-supply = <&reg_vref_3v3>;	/* VDD_IO */
	voltage-ranges = <3300 3300>;
	no-1-8-v;
	keep-power-in-suspend;
	status = "okay";
};
#endif /* CONFIG_ARMSTONEA9R4_SD_A */

#ifdef CONFIG_ARMSTONEA9R4_EMMC
&usdhc3 {
	pinctrl-names = "default";
	pinctrl-0 = <&pinctrl_usdhc3>;
	non-removable;
	bus-width = <8>;
	vmmc-supply = <&reg_vref_3v3>;	/* VDD */
	vqmmc-supply = <&reg_vref_3v3>;	/* VDD_IO */
	voltage-ranges = <3300 3300>;
	no-1-8-v;
	keep-power-in-suspend;
	status = "okay";
};
#endif

#ifdef CONFIG_ARMSTONEA9R4_HDMI
&hdmi_core {
#ifdef CONFIG_ARMSTONEA9R4_USE_ONE_IPU
	/*
	 * When using one IPU (id=0):
	 * HDMI can go to DI1, unless LVDS1 is also active. In this case LVDS1
	 * must go to DI1 and HDMI to DI0.
	 */
	ipu_id = <0>;
#if (__HDMI_ON_0_OR_1__ && __LVDS1_ON_0_OR_1__)
	disp_id = <0>;
#else
	disp_id = <1>;
#endif
#else /* !CONFIG_ARMSTONEA9R4_USE_ONE_IPU */
	/*
	 * When using two IPUs:
	 * HDMI can always go to IPU2 (id=1), DI1.
	 */
	disp_id = <1>;
	ipu_id = <0>;
#endif /* CONFIG_ARMSTONEA9R4_USE_ONE_IPU */
	status = "okay";
};
#endif

#if (defined(CONFIG_ARMSTONEA9R4_LVDS0) || defined(CONFIG_ARMSTONEA9R4_LVDS1))
&ldb {
	ext_ref;
#if defined(CONFIG_ARMSTONEA9R4_LVDS_SPLIT_MODE)
	split-mode;
#elif defined(CONFIG_ARMSTONEA9R4_LVDS_DUAL_MODE)
	dual-mode;
#endif
	ldb-supply = <&reg_vlcd>;
	status = "okay";

#ifdef CONFIG_ARMSTONEA9R4_LVDS0
	/* LVDS0 must always go to DI0 of an IPU! */
	lvds-channel@0 {
		reg = <0>;
#ifdef CONFIG_ARMSTONEA9R4_USE_ONE_IPU
		crtc = "ipu1-di0";
#else
		crtc = "ipu2-di0";
#endif
		fsl,data-mapping = CONFIG_ARMSTONEA9R4_LVDS0_MAPPING;
		fsl,data-width = <CONFIG_ARMSTONEA9R4_LVDS0_DATA_WIDTH>;
#ifdef __LVDS0_PRIMARY__
		primary;
#endif
		status = "okay";

		display-timings {
			native-mode = <&timing0>;
			timing0: CONFIG_ARMSTONEA9R4_LVDS0_TIMING;
		};
	};
#endif

#ifdef CONFIG_ARMSTONEA9R4_LVDS1
	/* LVDS1 must always go to DI1 of an IPU! */
	lvds-channel@1 {
#if defined(CONFIG_ARMSTONEA9R4_LVDS_DUAL_MODE) \
	|| defined(CONFIG_ARMSTONEA9R4_LVDS_SPLIT_MODE)
		reg = <0>;
#else
		reg = <1>;
#endif
#if (defined(CONFIG_ARMSTONEA9R4_USE_ONE_IPU) \
    || (__LVDS0_ON_0_OR_1__ && __LVDS1_ON_0_OR_1__))
		crtc = "ipu1-di1";
#else
		crtc = "ipu2-di1";
#endif
		fsl,data-mapping = CONFIG_ARMSTONEA9R4_LVDS1_MAPPING;
		fsl,data-width = <CONFIG_ARMSTONEA9R4_LVDS1_DATA_WIDTH>;
#ifdef __LVDS1_PRIMARY__
		primary;
#endif
		status = "okay";

		display-timings {
			native-mode = <&timing1>;
			timing1: CONFIG_ARMSTONEA9R4_LVDS1_TIMING;
		};
	};
#endif
};
#endif /* CONFIG_ARMSTONEA9R4_LVDS0 || CONFIG_ARMSTONEA9R4_LVDS1 */

#ifdef CONFIG_ARMSTONEA9R4_PCIE
&pcie {
	pinctrl-names = "default";
	pinctrl-0 = <&pinctrl_pcie>;
	disable-gpio = <&gpio2 28 GPIO_ACTIVE_LOW>;
	power-on-gpio = <&gpio6 16 GPIO_ACTIVE_LOW>;
	reset-gpio = <&gpio6 14 GPIO_ACTIVE_LOW>;
	status = "okay";
};
#endif

&iomuxc {
	pinctrl-names = "default";
	pinctrl-0 = <&pinctrl_hog_1>;

	imx6qdl-armstonea9r2 {
		/* Pin configs that don't belong anywhere else */
		pinctrl_hog_1: hoggrp-1 {
			fsl,pins = <
				/* GPIO 1 */
				MX6QDL_PAD_EIM_D23__GPIO3_IO23		0x030b0

				/* RS232, these pins for the level converter
				 * with these pins you can maybe save more
				 * current, not implemented yet */
				MX6QDL_PAD_EIM_BCLK__GPIO6_IO31		0x030b0
				MX6QDL_PAD_EIM_WAIT__GPIO5_IO00		0x030b0

				/* Audio clock */
				MX6QDL_PAD_GPIO_0__CCM_CLKO1		0x130b0

				/* Camera clock, ref. ov564x_mipi */
				MX6QDL_PAD_NANDF_CS2__CCM_CLKO2		0x130b0
				MX6QDL_PAD_CSI0_DAT6__GPIO5_IO24	0x17059

				/* VLCD_ON and 5V_3V3 (external Pull Up)
				 * for reg_vlcd */
				MX6QDL_PAD_SD4_DAT3__GPIO2_IO11		0x13059
				/* external Pull Down 22k no pull/keeper
				 * needed */
				MX6QDL_PAD_EIM_D30__GPIO3_IO30		0x000b0

				/* VBL_ON for backlight on */
				MX6QDL_PAD_SD4_DAT0__GPIO2_IO08		0x13059

				/* RTC_IRQ */
				MX6QDL_PAD_ENET_TX_EN__GPIO1_IO28	0x0b0b0

				/* I2C2_IRQ1 (Touch, Hirose) */
				MX6QDL_PAD_ENET_TXD0__GPIO1_IO30	0x0b0b0

				/* I2C2_IRQ2 (Touch, LVDS connector) */
				MX6QDL_PAD_SD4_DAT5__GPIO2_IO13		0x0b0b0

				/* I2C2_RSTn(Touch, LVDS connector) */
				MX6QDL_PAD_SD4_DAT6__GPIO2_IO14		0x0b0b0
			>;
		};

#if 0
		/* Pins already set in bootloader */
		pinctrl_gpmi_nand_1: gpmi-nand-1 {
			fsl,pins = <
				MX6QDL_PAD_NANDF_CLE__NAND_CLE		0x0b0b1
				MX6QDL_PAD_NANDF_ALE__NAND_ALE		0x0b0b1
				MX6QDL_PAD_NANDF_WP_B__NAND_WP_B	0x0b0b1
				MX6QDL_PAD_NANDF_RB0__NAND_READY_B	0x0b000
				MX6QDL_PAD_NANDF_CS0__NAND_CE0_B	0x0b0b1
				MX6QDL_PAD_SD4_CMD__NAND_RE_B		0x0b0b1
				MX6QDL_PAD_SD4_CLK__NAND_WE_B		0x0b0b1
				MX6QDL_PAD_NANDF_D0__NAND_DATA00	0x0b0b1
				MX6QDL_PAD_NANDF_D1__NAND_DATA01	0x0b0b1
				MX6QDL_PAD_NANDF_D2__NAND_DATA02	0x0b0b1
				MX6QDL_PAD_NANDF_D3__NAND_DATA03	0x0b0b1
				MX6QDL_PAD_NANDF_D4__NAND_DATA04	0x0b0b1
				MX6QDL_PAD_NANDF_D5__NAND_DATA05	0x0b0b1
				MX6QDL_PAD_NANDF_D6__NAND_DATA06	0x0b0b1
				MX6QDL_PAD_NANDF_D7__NAND_DATA07	0x0b0b1
			>;
		};
#endif

#ifdef CONFIG_ARMSTONEA9R4_SPI_FLASH
		/* ECSPI1 - SPI flash */
		pinctrl_ecspi1_1: ecspi1grp {
			fsl,pins = <
				MX6QDL_PAD_EIM_D17__ECSPI1_MISO		0x100b1
				MX6QDL_PAD_EIM_D18__ECSPI1_MOSI		0x100b1
				MX6QDL_PAD_EIM_D16__ECSPI1_SCLK		0x100b1
			>;
		};
		pinctrl_ecspi1_cs: ecspi1cs {
			fsl,pins = <
				/* ECSPI1_SS0 - slave (chip) select 0 */
				MX6QDL_PAD_EIM_EB2__GPIO2_IO30		0x1b0b0
			>;
		};
#endif /* CONFIG_ARMSTONEA9R4_SPI_FLASH */

#ifdef CONFIG_ARMSTONEA9R4_SPI_A
		/* ECSPI2 - SPI_A */
		pinctrl_ecspi2_1: ecspi2grp {
			fsl,pins = <
				MX6QDL_PAD_EIM_OE__ECSPI2_MISO		0x100b1
				MX6QDL_PAD_EIM_CS1__ECSPI2_MOSI		0x100b1
				MX6QDL_PAD_EIM_CS0__ECSPI2_SCLK		0x100b1
			>;
		};
		pinctrl_ecspi2_cs: ecspi2cs {
			fsl,pins = <
				/* ECSPI2_SS0 - slave (chip) select 0 */
				MX6QDL_PAD_EIM_RW__GPIO2_IO26		0x1b0b0
			>;
		};
#endif /* CONFIG_ARMSTONEA9R4_SPI_A */

#ifdef CONFIG_ARMSTONEA9R4_SPI_B
		/* ECSPI3 - SPI_B */
		pinctrl_ecspi3_1: ecspi3grp {
			fsl,pins = <
				MX6QDL_PAD_DISP0_DAT2__ECSPI3_MISO	0x100b1
				MX6QDL_PAD_DISP0_DAT1__ECSPI3_MOSI	0x100b1
				MX6QDL_PAD_DISP0_DAT0__ECSPI3_SCLK	0x100b1
			>;
		};
		pinctrl_ecspi3_cs: ecspi3cs {
			fsl,pins = <
				/* ECSPI3_SS0 - slave (chip) select 0 */
				MX6QDL_PAD_DISP0_DAT3__ECSPI3_SS0	0x1b0b0
			>;
		};
#endif /* CONFIG_ARMSTONEA9R4_SPI_B */

#ifdef CONFIG_ARMSTONEA9R4_UART_A
		/* UART2 on pins 19,21,23,25 */
		pinctrl_uart2_1: uart2grp-1{
			fsl,pins = <
				MX6QDL_PAD_EIM_D26__UART2_TX_DATA	0x1b0b1
				MX6QDL_PAD_EIM_D27__UART2_RX_DATA	0x1b0b1
#ifdef CONFIG_ARMSTONEA9R4_UART_A_RTSCTS
				MX6QDL_PAD_EIM_D28__UART2_CTS_B		0x1b0b1
				MX6QDL_PAD_EIM_D29__UART2_RTS_B		0x1b0b1
#endif /* CONFIG_ARMSTONEA9R4_UART_A_RTSCTS */
			>;
		};
#endif /* CONFIG_ARMSTONEA9R4_UART_A */

#ifdef CONFIG_ARMSTONEA9R4_UART_B
		/* UART1 on pins 13, 15 (port B)*/
		pinctrl_uart1_1: uart1grp-1{
			fsl,pins = <
				MX6QDL_PAD_CSI0_DAT10__UART1_TX_DATA	0x1b0b1
				MX6QDL_PAD_CSI0_DAT11__UART1_RX_DATA	0x1b0b1
#ifdef CONFIG_ARMSTONEA9R4_UART_B_RTSCTS
				MX6QDL_PAD_EIM_D19__UART1_CTS_B		0x1b0b1
				MX6QDL_PAD_EIM_D20__UART1_RTS_B		0x1b0b1
#endif
			>;
		};
#endif /* CONFIG_ARMSTONEA9R4_UART_B */

#ifdef CONFIG_ARMSTONEA9R4_UART_C
		/* UART3 on pins 36, 38 (port C) */
		pinctrl_uart3_1: uart3grp-1{
			fsl,pins = <
				MX6QDL_PAD_EIM_D24__UART3_TX_DATA	0x1b0b1
				MX6QDL_PAD_EIM_D25__UART3_RX_DATA	0x1b0b1
			>;
		};
#endif /* CONFIG_ARMSTONEA9R4_UART_C */

#ifdef CONFIG_ARMSTONEA9R4_UART_D
		/* UART2 on pins 55-58 (debug port D)*/
		pinctrl_uart4_1: uart4grp-1{
			fsl,pins = <
				MX6QDL_PAD_KEY_COL0__UART4_TX_DATA	0x1b0b1
				MX6QDL_PAD_KEY_ROW0__UART4_RX_DATA	0x1b0b1
#ifdef CONFIG_ARMSTONEA9R4_UART_D_RTSCTS
				MX6QDL_PAD_CSI0_DAT17__UART4_CTS_B	0x1b0b1
				MX6QDL_PAD_CSI0_DAT16__UART4_RTS_B	0x1b0b1
#endif /* CONFIG_ARMSTONEA9R4_UART_D_RTSCTS */
			>;
		};
#endif /* CONFIG_ARMSTONEA9R4_UART_D */

#ifdef CONFIG_ARMSTONEA9R4_UART_E
		/* UART5 on pins 36, 38 (port C) */
		pinctrl_uart5_1: uart5grp-1{
			fsl,pins = <
				MX6QDL_PAD_KEY_COL1__UART5_TX_DATA	0x1b0b1
				MX6QDL_PAD_KEY_ROW1__UART5_RX_DATA	0x1b0b1
			>;
		};
#endif /* CONFIG_ARMSTONEA9R4_UART_E */

		/* CAN A */
		pinctrl_flexcan_a: flexcan2grp {
			fsl,pins = <
				MX6QDL_PAD_KEY_COL4__FLEXCAN2_TX	0x1b020
				MX6QDL_PAD_KEY_ROW4__FLEXCAN2_RX	0x1b020
			>;
		};

		/* CAN B */
		pinctrl_flexcan_b: flexcan1grp {
			fsl,pins = <
				MX6QDL_PAD_KEY_COL2__FLEXCAN1_TX	0x1b020
				MX6QDL_PAD_KEY_ROW2__FLEXCAN1_RX	0x1b020
			>;
		};

		pinctrl_usbotg: usbotggrp {
			fsl,pins = <
				/* USB_OTG_PWR, active low */
//###				MX6QDL_PAD_EIM_D22__GPIO3_IO22		0x0b030
				MX6QDL_PAD_EIM_D22__USB_OTG_PWR		0x0b030
				/* USB_OTG_ID: low: host, open: device */
				MX6QDL_PAD_ENET_RX_ER__USB_OTG_ID 	0x1b000
			>;
		};

		pinctrl_usbh1: usbh1grp {
			fsl,pins = <
				/* USB hub reset line, active low */
				MX6QDL_PAD_EIM_EB1__GPIO2_IO29		0x0b0b0
				/* USB H1 host power is always on */
			>;
		};

		pinctrl_enet: enetgrp {
			fsl,pins = <
				MX6QDL_PAD_ENET_MDIO__ENET_MDIO		0x1b0b0
				MX6QDL_PAD_ENET_MDC__ENET_MDC		0x1b0b0
				MX6QDL_PAD_RGMII_TXC__RGMII_TXC		0x1b0b0
				MX6QDL_PAD_RGMII_TD0__RGMII_TD0		0x1b0b0
				MX6QDL_PAD_RGMII_TD1__RGMII_TD1		0x1b0b0
				MX6QDL_PAD_RGMII_TD2__RGMII_TD2		0x1b0b0
				MX6QDL_PAD_RGMII_TD3__RGMII_TD3		0x1b0b0
				MX6QDL_PAD_RGMII_TX_CTL__RGMII_TX_CTL	0x1b0b0
				MX6QDL_PAD_ENET_REF_CLK__ENET_TX_CLK	0x1b0b0
				MX6QDL_PAD_RGMII_RXC__RGMII_RXC		0x1b0b0
				MX6QDL_PAD_RGMII_RD0__RGMII_RD0		0x1b0b0
				MX6QDL_PAD_RGMII_RD1__RGMII_RD1		0x1b0b0
				MX6QDL_PAD_RGMII_RD2__RGMII_RD2		0x1b0b0
				MX6QDL_PAD_RGMII_RD3__RGMII_RD3		0x1b0b0
				MX6QDL_PAD_RGMII_RX_CTL__RGMII_RX_CTL	0x1b0b0
				/* Phy interrupt IO pin*/
				MX6QDL_PAD_GPIO_19__GPIO4_IO05		0x4001b0a8
				/* Phy reset IO pin*/
				MX6QDL_PAD_ENET_CRS_DV__GPIO1_IO25	0x4001b0a8
			>;
		};

#ifdef CONFIG_ARMSTONEA9R4_I2C_A
		/* I2C_A: Feature Connector (SKIT) */
		pinctrl_i2c3: i2c3grp-1 {
			fsl,pins = <
				MX6QDL_PAD_GPIO_3__I2C3_SCL		0x4001b8b1
				MX6QDL_PAD_GPIO_16__I2C3_SDA		0x4001b8b1
				/* if AD Converter */
				//MX6QDL_PAD_SD4_DAT4__GPIO2_IO12	0x0b0b0
			>;
		};
#endif /* CONFIG_ARMSTONEA9R4_I2C_A */

#ifdef CONFIG_ARMSTONEA9R4_I2C_B
		/* I2C2 as I2C port B  (DataFlash, PMIC) */
		pinctrl_i2c2: i2c2grp {
			fsl,pins = <
				MX6QDL_PAD_KEY_COL3__I2C2_SCL		0x4001b8b1
				MX6QDL_PAD_KEY_ROW3__I2C2_SDA		0x4001b8b1
			>;
		};
#endif /* CONFIG_ARMSTONEA9R4_I2C_B */

#ifdef CONFIG_ARMSTONEA9R4_I2C_C
		/* I2C_C: additonal bus on pins 18 and 26 (RTC) */
		pinctrl_i2c1: i2c1grp {
			fsl,pins = <
				MX6QDL_PAD_CSI0_DAT8__I2C1_SDA		0x4001b8b1
				MX6QDL_PAD_CSI0_DAT9__I2C1_SCL		0x4001b8b1
			>;
		};
#endif /* CONFIG_ARMSTONEA9R4_I2C_C */

#ifdef CONFIG_ARMSTONEA9R4_I2C_D
		/* I2C_D: additonal bus on pins 8 and 10. Shared with ECSPI3 */
		pinctrl_i2c4: i2c4grp {
			fsl,pins = <
				MX6QDL_PAD_GPIO_8__I2C4_SDA		0x4001b8b1
				MX6QDL_PAD_GPIO_7__I2C4_SCL		0x4001b8b1
			>;
		};
#endif /* CONFIG_ARMSTONEA9R4_I2C_D */

#if defined(CONFIG_ARMSTONEA9R4_SGTL5000_AUDIO)
		pinctrl_audmux_4: audmux-4 {
			fsl,pins = <
				MX6QDL_PAD_DISP0_DAT20__AUD4_TXC	0x130b0
				MX6QDL_PAD_DISP0_DAT21__AUD4_TXD	0x130b0
				MX6QDL_PAD_DISP0_DAT22__AUD4_TXFS	0x130b0
				MX6QDL_PAD_DISP0_DAT23__AUD4_RXD	0x130b0
			>;
		};
#endif

#ifdef CONFIG_ARMSTONEA9R4_HDMI_CEC
		pinctrl_hdmi_cec_1: hdmicecgrp {
			fsl,pins = <
				MX6QDL_PAD_EIM_A25__HDMI_TX_CEC_LINE	0x1f8b0
			>;
		};
#endif /* CONFIG_ARMSTONEA9R4_HDMI_CEC */

		/* PWM port C - PWM1 */
		pinctrl_pwm1_1: pwm1grp {
			fsl,pins = <
				MX6QDL_PAD_DISP0_DAT8__PWM1_OUT		0x110b0
			>;
		};

		/* PWM port A - PWM2 */
		pinctrl_pwm2_1: pwm2grp {
			fsl,pins = <
				MX6QDL_PAD_DISP0_DAT9__PWM2_OUT		0x110b0
			>;
		};

		/* LVDS backlight control - PWM3 */
		pinctrl_pwm3_1: pwm3grp {
			fsl,pins = <
				MX6QDL_PAD_SD4_DAT1__PWM3_OUT		0x110b0
			>;
		};

		/* PWM port B - PWM4 */
		pinctrl_pwm4_1: pwm4grp {
			fsl,pins = <
				MX6QDL_PAD_SD4_DAT2__PWM4_OUT		0x110b0
			>;
		};
#if 0
		pinctrl_gpio_matrix_keypad: g-m-kgrp {
			fsl,pins = <
				/* rows */
				MX6QDL_PAD_CSI0_DAT10__GPIO5_IO28	0x80000000
				MX6QDL_PAD_EIM_D28__GPIO3_IO28		0x80000000
				MX6QDL_PAD_CSI0_DAT11__GPIO5_IO29	0x80000000
				MX6QDL_PAD_EIM_D29__GPIO3_IO29		0x80000000
				MX6QDL_PAD_EIM_D19__GPIO3_IO19		0x80000000
				MX6QDL_PAD_EIM_D24__GPIO3_IO24		0x80000000
				MX6QDL_PAD_EIM_D20__GPIO3_IO20		0x80000000
				MX6QDL_PAD_EIM_D25__GPIO3_IO25		0x80000000
				/* columns */
				MX6QDL_PAD_DISP0_DAT0__GPIO4_IO21	0x80000000
				MX6QDL_PAD_EIM_DA0__GPIO3_IO00		0x030b0
				MX6QDL_PAD_EIM_DA1__GPIO3_IO01		0x030b0
				MX6QDL_PAD_EIM_DA2__GPIO3_IO02		0x030b0
				MX6QDL_PAD_EIM_DA3__GPIO3_IO03		0x030b0
				MX6QDL_PAD_DISP0_DAT1__GPIO4_IO22	0x80000000
				MX6QDL_PAD_DISP0_DAT2__GPIO4_IO23	0x80000000
				MX6QDL_PAD_DISP0_DAT3__GPIO4_IO24	0x80000000
			>;
		};
#endif

#ifdef CONFIG_ARMSTONEA9R4_WLAN
		pinctrl_usdhc1:usdhc1grp {
			fsl,pins = <
				MX6QDL_PAD_SD1_CMD__SD1_CMD		0x17091
				MX6QDL_PAD_SD1_CLK__SD1_CLK		0x10091
				MX6QDL_PAD_SD1_DAT0__SD1_DATA0		0x17091
				MX6QDL_PAD_SD1_DAT1__SD1_DATA1		0x17091
				MX6QDL_PAD_SD1_DAT2__SD1_DATA2		0x17091
				MX6QDL_PAD_SD1_DAT3__SD1_DATA3		0x17091
				/* CD, active low */
				MX6QDL_PAD_GPIO_1__GPIO1_IO01		0x17000
				/* WLAN_RESET, has external pull-down */
				MX6QDL_PAD_ENET_RXD0__GPIO1_IO27	0x100b0
			>;
		};
#endif /* CONFIG_ARMSTONEA9R4_WLAN */

#ifdef CONFIG_ARMSTONEA9R4_SD_A
		pinctrl_usdhc2: usdhc2grp {
			fsl,pins = <
				MX6QDL_PAD_SD2_CMD__SD2_CMD		0x170b1
				MX6QDL_PAD_SD2_CLK__SD2_CLK		0x100b1
				MX6QDL_PAD_SD2_DAT0__SD2_DATA0		0x170b1
				MX6QDL_PAD_SD2_DAT1__SD2_DATA1		0x170b1
				MX6QDL_PAD_SD2_DAT2__SD2_DATA2		0x170b1
				MX6QDL_PAD_SD2_DAT3__SD2_DATA3		0x170b1
				/* Card Detect (CD), active low (pull-up) */
				MX6QDL_PAD_GPIO_4__GPIO1_IO04		0x17000
			>;
		};
#endif /* CONFIG_ARMSTONEA9R4_SD_A */

#ifdef CONFIG_ARMSTONEA9R4_EMMC
		pinctrl_usdhc3: usdhc3grp {
			fsl,pins = <
				MX6QDL_PAD_SD3_CMD__SD3_CMD		0x17091
				MX6QDL_PAD_SD3_CLK__SD3_CLK		0x10091
				MX6QDL_PAD_SD3_DAT0__SD3_DATA0		0x17091
				MX6QDL_PAD_SD3_DAT1__SD3_DATA1		0x17091
				MX6QDL_PAD_SD3_DAT2__SD3_DATA2		0x17091
				MX6QDL_PAD_SD3_DAT3__SD3_DATA3		0x17091
				MX6QDL_PAD_SD3_DAT4__SD3_DATA4		0x17091
				MX6QDL_PAD_SD3_DAT5__SD3_DATA5		0x17091
				MX6QDL_PAD_SD3_DAT6__SD3_DATA6		0x17091
				MX6QDL_PAD_SD3_DAT7__SD3_DATA7		0x17091
				/* Reset eMMC, active low */
				MX6QDL_PAD_SD3_RST__SD3_RESET		0x17091
			>;
		};
#endif /* CONFIG_ARMSTONEA9R4_EMMC */

#ifdef CONFIG_ARMSTONEA9R4_PCIE
		pinctrl_pcie: pciegrp {
			fsl,pins = <
				/* PCIe-DIS */
				MX6QDL_PAD_EIM_EB0__GPIO2_IO28		0x1b0b0
				/* PCIe-RST */
				MX6QDL_PAD_NANDF_CS1__GPIO6_IO14	0x1b0b0
				/* PCIe-WAKE */
				MX6QDL_PAD_NANDF_CS3__GPIO6_IO16	0x1b0b0
			>;
		};
#endif /* CONFIG_ARMSTONEA9R4_PCIE */

		pinctrl_status_leds: ledgrp {
			fsl,pins = <
				MX6QDL_PAD_GPIO_17__GPIO7_IO12		0x030b0
				MX6QDL_PAD_GPIO_18__GPIO7_IO13		0x030b0
			>;
		};
	};
};
